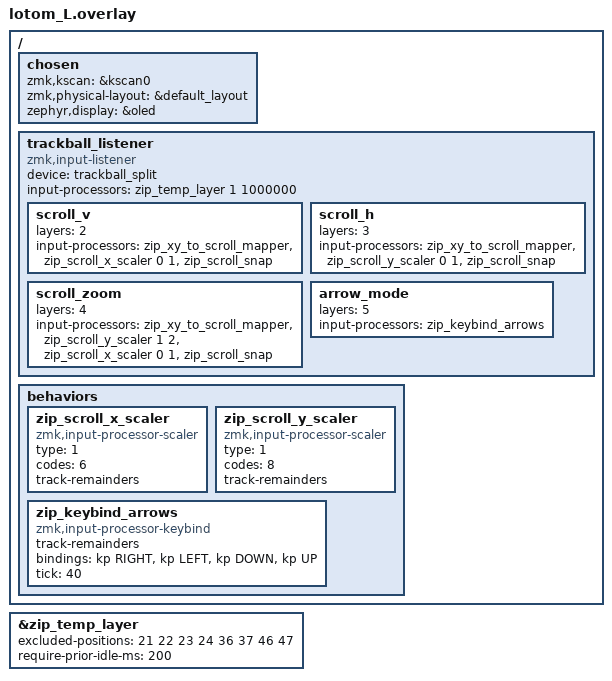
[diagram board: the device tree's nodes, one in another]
#include <dt-bindings/zmk/matrix_transform.h>
#include <dt-bindings/zmk/input_transform.h>
#include <input/processors.dtsi>
#include <zephyr/dt-bindings/input/input-event-codes.h>
#include <physical_layouts.dtsi>
#include <scroll-snap.dtsi>
#include "lotom.dtsi"

&zip_temp_layer {
    excluded-positions = <
        21 // J
        22 // K
        23 // l
        24 // -
        36 // /
        37 // shift
        46 // [
        47 // ]
    >;
};

/ {
    chosen {
        zmk,kscan = &kscan0;
        zmk,physical-layout = &default_layout;
        zephyr,display = &oled;
    };

    /* --- 中略 (kscan0, split_inputs, encoders, sensors) --- */
    /* ※この部分は現在のファイルの内容を維持してください */

    trackball_listener: trackball_listener {
        compatible = "zmk,input-listener";
        status = "disabled";
        device = <&trackball_split>;
    };

    /* カスタム挙動の定義 */
    behaviors {
        zip_scroll_x_scaler: zip_scroll_x_scaler {
            compatible = "zmk,input-processor-scaler";
            #input-processor-cells = <2>;
            type = <1>; 
            codes = <6>; 
            track-remainders;
        };

        zip_scroll_y_scaler: zip_scroll_y_scaler {
            compatible = "zmk,input-processor-scaler";
            #input-processor-cells = <2>;
            type = <1>; 
            codes = <8>; 
            track-remainders;
        };

        zip_keybind_arrows: zip_keybind_arrows {
            compatible = "zmk,input-processor-keybind";
            #input-processor-cells = <0>;
            track-remainders;
            bindings = <&kp RIGHT>, <&kp LEFT>, <&kp DOWN>, <&kp UP>;
            tick = <40>;
        };
    };
};

/* リスナーの設定 */
&trackball_listener {
    status = "okay";
    input-processors = <&zip_temp_layer 1 1000000>;

    scroll_v {
        layers = <2>;
        input-processors = <&zip_xy_to_scroll_mapper>, <&zip_scroll_x_scaler 0 1>, <&zip_scroll_snap>;
    };

    scroll_h {
        layers = <3>;
        input-processors = <&zip_xy_to_scroll_mapper>, <&zip_scroll_y_scaler 0 1>, <&zip_scroll_snap>;
    };

    scroll_zoom {
        layers = <4>;
        input-processors = <&zip_xy_to_scroll_mapper>, <&zip_scroll_y_scaler 1 2>, <&zip_scroll_x_scaler 0 1>, <&zip_scroll_snap>;
    };

    arrow_mode {
        layers = <5>;
        input-processors = <&zip_keybind_arrows>;
    };
};

&zip_temp_layer { require-prior-idle-ms = <200>; };

/* --- 以降、I2C/OLED設定 (変更なし) --- */
